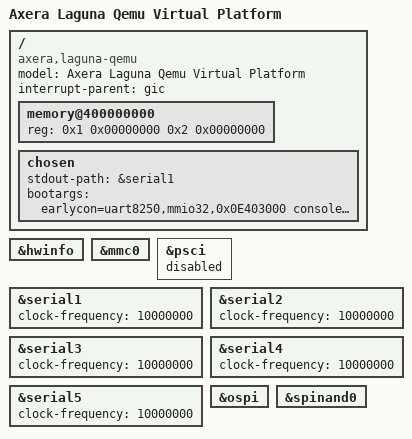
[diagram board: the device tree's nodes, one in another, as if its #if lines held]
/* SPDX-License-Identifier: GPL-2.0+
 *
 * Axera Laguna Qemu Virtual Platform device tree
 *
 * Copyright (C) 2024 Charleye <wangkart@aliyun.com>
 */

/dts-v1/;
#include <dt-bindings/interrupt-controller/arm-gic.h>
#include <dt-bindings/mfd/laguna-syscon.h>
#include <dt-bindings/mfd/laguna-cru.h>
#include <dt-bindings/reset/laguna-reset.h>
#include <dt-bindings/clock/laguna-clock.h>

#ifdef CONFIG_LUA_SAFETY_INIT
#include "laguna-safety-clocks-fpga.dtsi"
#include "laguna-safety-cru.dtsi"
#include "laguna-safety.dtsi"
#endif

#include "laguna-global-ctrl.dtsi"
#include "laguna-clocks-fpga.dtsi"
#include "laguna-cru.dtsi"
#include "laguna.dtsi"

/ {
	compatible = "axera,laguna-qemu";
	model = "Axera Laguna Qemu Virtual Platform";
	#address-cells = <2>;
	#size-cells = <2>;
	interrupt-parent = <&gic>;

	memory@400000000 {
		reg = <0x1 0x00000000 0x2 0x00000000>;
		device_type = "memory";
	};

	chosen {
		stdout-path = &serial1;
		bootargs = "earlycon=uart8250,mmio32,0x0E403000 console=ttyS1,115200n8 rdinit=/init rw loglevel=10";
	};
};

&hwinfo {
	status = "okay";
};

&mmc0 {
	status = "okay";
};

&psci {
	status = "disabled";
};

&serial1 {
	clock-frequency = <10000000>; //10MHz
	status = "okay";
};

&serial2 {
	clock-frequency = <10000000>; //10MHz
	status = "okay";
};

&serial3 {
	clock-frequency = <10000000>; //10MHz
	status = "okay";
};

&serial4 {
	clock-frequency = <10000000>; //10MHz
	status = "okay";
};

&serial5 {
	clock-frequency = <10000000>; //10MHz
	status = "okay";
};

&ospi {
	status = "okay";
};

&spinand0 {
	status = "okay";
};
